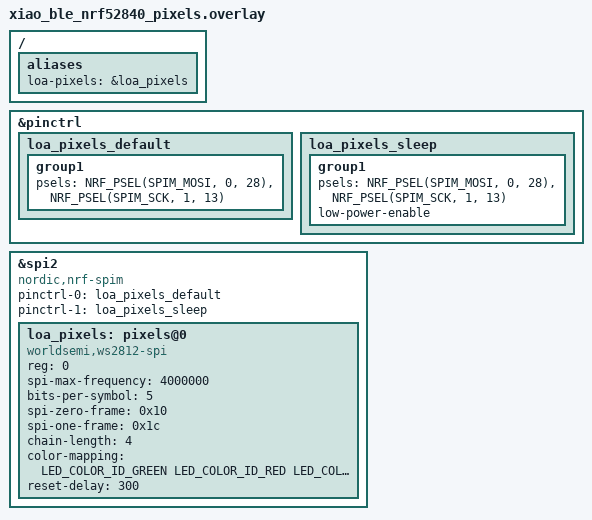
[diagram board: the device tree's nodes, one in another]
/* Four front GRB NeoPixels, XIAO D2/P0.28, through MODE and 330 ohms.
 * 4 MHz SPI, five bits per symbol: 1.25 us bit time, T0H=250 ns,
 * T1H=750 ns. MOSI drives D2; clock uses the unconnected D8 pad.
 */
#include <zephyr/dt-bindings/led/led.h>

/ {
	aliases {
		loa-pixels = &loa_pixels;
	};
};

&pinctrl {
	loa_pixels_default: loa_pixels_default {
		group1 {
			psels = <NRF_PSEL(SPIM_MOSI, 0, 28)>, <NRF_PSEL(SPIM_SCK, 1, 13)>;
		};
	};
	loa_pixels_sleep: loa_pixels_sleep {
		group1 {
			psels = <NRF_PSEL(SPIM_MOSI, 0, 28)>, <NRF_PSEL(SPIM_SCK, 1, 13)>;
			low-power-enable;
		};
	};
};

&spi2 {
	compatible = "nordic,nrf-spim";
	status = "okay";
	pinctrl-0 = <&loa_pixels_default>;
	pinctrl-1 = <&loa_pixels_sleep>;
	pinctrl-names = "default", "sleep";
	loa_pixels: pixels@0 {
		compatible = "worldsemi,ws2812-spi";
		reg = <0>;
		spi-max-frequency = <4000000>;
		bits-per-symbol = <5>;
		spi-zero-frame = <0x10>;
		spi-one-frame = <0x1c>;
		chain-length = <4>;
		color-mapping = <LED_COLOR_ID_GREEN LED_COLOR_ID_RED LED_COLOR_ID_BLUE>;
		reset-delay = <300>;
	};
};
